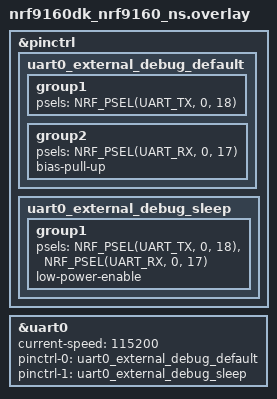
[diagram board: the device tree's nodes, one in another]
/*
 * Copyright (c) 2023 Nordic Semiconductor ASA
 *
 * SPDX-License-Identifier: LicenseRef-Nordic-5-Clause
 */

/* Enable uart1 for tracing. */



&pinctrl {
	uart0_external_debug_default: uart0_external_debug_default {
			group1 {
					psels = <NRF_PSEL(UART_TX, 0, 18)>;
			};
			group2 {
					psels = <NRF_PSEL(UART_RX, 0, 17)>;
					bias-pull-up;
			};
			/delete-property/ hw-flow-control;
	};

	uart0_external_debug_sleep: uart0_external_debug_sleep {
			group1 {
					psels = <NRF_PSEL(UART_TX, 0, 18)>,
							<NRF_PSEL(UART_RX, 0, 17)>;
					low-power-enable;
					/delete-property/ hw-flow-control;
			};
	};




};

/* AT command interface - set to  uart0_external_debug_default for external header pins or uart0_netapp_default */
&uart0 {
	status = "okay";
	current-speed = <115200>;
	pinctrl-0 = <&uart0_external_debug_default>;
	pinctrl-1 = <&uart0_external_debug_sleep>;
	pinctrl-names = "default", "sleep";
};


